AUTOSAR XML (schema 00049)
package /DataType/Implementation/CPP
  11 x std cpp implementation data type:
    bool: category=VALUE, type-emitter=FundamentalType
    float: category=VALUE, type-emitter=FundamentalType
    uint8_t: category=VALUE, header-file=cstdint
    uint32_t: category=VALUE, header-file=cstdint
    uint64_t: category=VALUE, header-file=cstdint
    String: category=STRING, header-file=ara/core/string.h
      namespaces:
        symbol props ara
        symbol props core
    SpeedData: category=STRUCTURE, header-file=vehicle_data/types.hpp
      namespaces:
        symbol props vehicle_data
      cpp implementation data type element speed_kmh: type-reference=float
      cpp implementation data type element timestamp_us: type-reference=uint64_t
    CabinSensorData: category=STRUCTURE, header-file=vehicle_data/types.hpp
      namespaces:
        symbol props vehicle_data
      cpp implementation data type element temperature_c: type-reference=float
      cpp implementation data type element humidity_pct: type-reference=float
      cpp implementation data type element passenger_detected: type-reference=bool
    EmergencyAlert: category=STRUCTURE, header-file=vehicle_data/types.hpp
      namespaces:
        symbol props vehicle_data
      cpp implementation data type element alert_id: type-reference=uint32_t
      cpp implementation data type element reason: type-reference=String
    DriveMode: compu {0=ECO, 1=COMFORT, 2=SPORT, 3=EMERGENCY}, header-file=vehicle_data/types.hpp, type-reference=uint8_t
      namespaces:
        symbol props vehicle_data
    LocationPoint: category=STRUCTURE, header-file=vehicle_data/types.hpp
      namespaces:
        symbol props vehicle_data
      4 x cpp implementation data type element, all with category=TYPE_REFERENCE, type-reference=float:
        latitude
        longitude
        altitude
        speed_limit_kmh
package /PortInterface/Service
  5 x service interface:
    PowertrainInterface
      namespaces:
        symbol props powertrain
      events:
        data VehicleSpeed: type=SpeedData
        data CabinSensors: type=CabinSensorData
    BodyControlInterface
      namespaces:
        symbol props body_control
      4 x field, all with has-notifier=true:
        TargetCabinTemperature: type=float, has-getter=true, has-setter=true
        RainSensorLevel: type=uint32_t, has-getter=false, has-setter=false
        OutsideAirQuality: type=uint32_t, has-getter=true, has-setter=false
        WindowPosition: type=uint32_t, has-getter=false, has-setter=true
      methods:
        operation LockDoors
          arg lock: type=bool, direction=IN
          arg Result: type=bool, direction=OUT
        operation FlashLights: fire-and-forget=true
          arg duration_ms: type=uint32_t, direction=IN
          arg count: type=uint32_t, direction=IN
    NavigationInterface
      namespaces:
        symbol props infotainment
        symbol props geo
        symbol props navigation
      events:
        data CurrentLocation: type=LocationPoint
      methods:
        operation SetDestination
          4 x arg:
            latitude: type=float, direction=IN
            longitude: type=float, direction=IN
            priority: type=uint32_t, direction=IN
            Result: type=bool, direction=OUT
    VehicleSupervisorInterface
      namespaces:
        symbol props vehicle_supervisor
      events:
        data EmergencyAlert: type=EmergencyAlert
      field CurrentDriveMode: type=DriveMode, has-getter=true, has-notifier=false, has-setter=true
      field HardwareRevision: type=uint32_t, has-getter=true, has-notifier=false, has-setter=false
      field CalibrationKey: type=uint32_t, has-getter=false, has-notifier=false, has-setter=true
      methods:
        4 x operation:
          TriggerDiagnostic
            arg code: type=uint32_t, direction=IN
            arg Result: type=bool, direction=OUT
          CalibrateOdometer
            arg current_km: type=uint32_t, direction=IN
            arg Result: type=uint32_t, direction=OUT
          ResetTripMeter: fire-and-forget=true
          SetSpeedLimiter
            arg max_kmh: type=float, direction=IN
            arg active: type=bool, direction=IN
            arg Result: type=bool, direction=OUT
    HmiServiceInterface
      namespaces:
        symbol props hmi
      events:
        data StatusNotification: type=String
      methods:
        operation ShowPopup
          arg message: type=String, direction=IN
          arg priority: type=uint32_t, direction=IN
          arg Result: type=bool, direction=OUT
package /PortInterface/PlatformInterfaces
  persistency file storage interface LogFileStorage
  persistency key value storage interface VehicleSettingsStorage
  phm health channel interface SystemHealthChannel
  phm supervised entity interface WatchdogSupervisedEntity
package /SwComponent/AdaptiveApplication
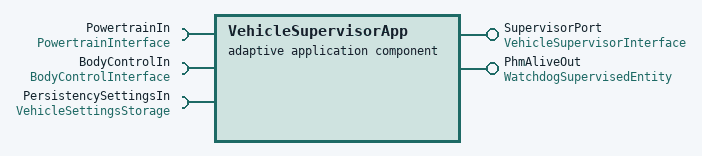
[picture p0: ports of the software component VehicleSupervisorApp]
  adaptive application sw component type VehicleSupervisorApp
    provide port SupervisorPort: provided-interface=VehicleSupervisorInterface
    provide port PhmAliveOut: provided-interface=WatchdogSupervisedEntity
    require port PowertrainIn: required-interface=PowertrainInterface
    require port BodyControlIn: required-interface=BodyControlInterface
    require port PersistencySettingsIn: required-interface=VehicleSettingsStorage
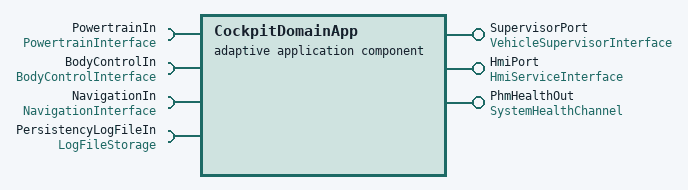
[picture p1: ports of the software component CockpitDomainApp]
  adaptive application sw component type CockpitDomainApp
    provide port SupervisorPort: provided-interface=VehicleSupervisorInterface
    provide port HmiPort: provided-interface=HmiServiceInterface
    provide port PhmHealthOut: provided-interface=SystemHealthChannel
    4 x require port:
      PowertrainIn: required-interface=PowertrainInterface
      BodyControlIn: required-interface=BodyControlInterface
      NavigationIn: required-interface=NavigationInterface
      PersistencyLogFileIn: required-interface=LogFileStorage
  adaptive application sw component type TelemetryApp
    provide port SupervisorPort: provided-interface=VehicleSupervisorInterface
package /Deployment
  executable VehicleSupervisor
    root sw component prototype RootSwComponent: application-type=VehicleSupervisorApp
  executable CockpitDomain
    root sw component prototype RootSwComponent: application-type=CockpitDomainApp
  executable Telemetry
    root sw component prototype RootSwComponent: application-type=TelemetryApp
